# STM32L496 register map
File version: 1.0
CPU: CM4 r0p1, little endian, MPU, FPU, 4 interrupt priority bits
Registers are 32-bit, read-write, reset 0x0 unless marked. A register's access mark holds for its fields unless they carry their own. Offsets are from the block's base; [hi:lo] are bit positions; {n}, {i} and the like mark numbered series; 'fields as' and 'values as' point back to an identical list.

## USART1 — Universal synchronous asynchronous receiver transmitter
Base 0x40013800
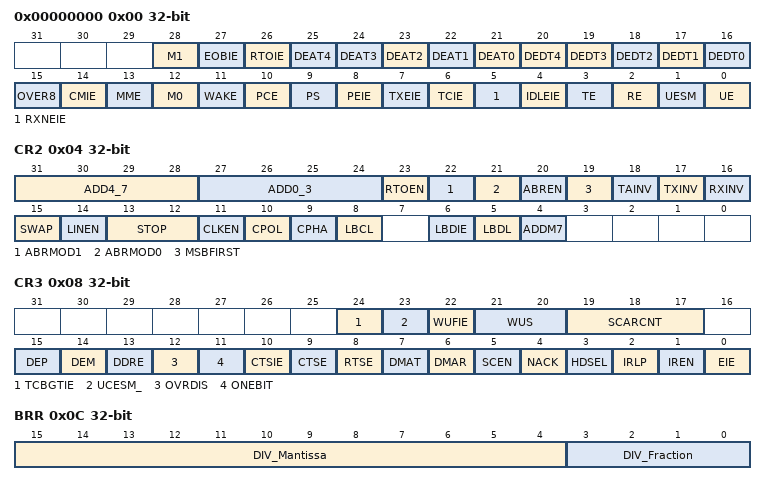
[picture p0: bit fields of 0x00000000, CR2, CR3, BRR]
0x00 0x00000000 — Control register 1
  [28] M1 — Word length
  [27] EOBIE — End of Block interrupt enable
  [26] RTOIE — Receiver timeout interrupt enable
  [25] DEAT4 — Driver Enable assertion time
  [n+21] DEAT{n} (n=0..3)
  [20] DEDT4 — Driver Enable de-assertion time
  [n+16] DEDT{n} (n=0..3)
  [15] OVER8 — Oversampling mode
  [14] CMIE — Character match interrupt enable
  [13] MME — Mute mode enable
  [12] M0 — Word length
  [11] WAKE — Receiver wakeup method
  [10] PCE — Parity control enable
  [9] PS — Parity selection
  [8] PEIE — PE interrupt enable
  [7] TXEIE — interrupt enable
  [6] TCIE — Transmission complete interrupt enable
  [5] RXNEIE — RXNE interrupt enable
  [4] IDLEIE — IDLE interrupt enable
  [3] TE — Transmitter enable
  [2] RE — Receiver enable
  [1] UESM — USART enable in Stop mode
  [0] UE — USART enable
0x04 CR2 — Control register 2
  [31:28] ADD4_7 — Address of the USART node
  [27:24] ADD0_3 — Address of the USART node
  [23] RTOEN — Receiver timeout enable
  [22] ABRMOD1 — Auto baud rate mode
  [21] ABRMOD0
  [20] ABREN — Auto baud rate enable
  [19] MSBFIRST — Most significant bit first
  [18] TAINV — Binary data inversion
  [17] TXINV — TX pin active level inversion
  [16] RXINV — RX pin active level inversion
  [15] SWAP — Swap TX/RX pins
  [14] LINEN — LIN mode enable
  [13:12] STOP — STOP bits
  [11] CLKEN — Clock enable
  [10] CPOL — Clock polarity
  [9] CPHA — Clock phase
  [8] LBCL — Last bit clock pulse
  [6] LBDIE — LIN break detection interrupt enable
  [5] LBDL — LIN break detection length
  [4] ADDM7 — 7-bit Address Detection/4-bit Address Detection
0x08 CR3 — Control register 3
  [24] TCBGTIE — Transmission complete before guard time interrupt enable
  [23] UCESM_ — USART Clock Enable in Stop mode.
  [22] WUFIE — Wakeup from Stop mode interrupt enable
  [21:20] WUS — Wakeup from Stop mode interrupt flag selection
  [19:17] SCARCNT — Smartcard auto-retry count
  [15] DEP — Driver enable polarity selection
  [14] DEM — Driver enable mode
  [13] DDRE — DMA Disable on Reception Error
  [12] OVRDIS — Overrun Disable
  [11] ONEBIT — One sample bit method enable
  [10] CTSIE — CTS interrupt enable
  [9] CTSE — CTS enable
  [8] RTSE — RTS enable
  [7] DMAT — DMA enable transmitter
  [6] DMAR — DMA enable receiver
  [5] SCEN — Smartcard mode enable
  [4] NACK — Smartcard NACK enable
  [3] HDSEL — Half-duplex selection
  [2] IRLP — Ir low-power
  [1] IREN — Ir mode enable
  [0] EIE — Error interrupt enable
0x0C BRR — Baud rate register
  [15:4] DIV_Mantissa, [3:0] DIV_Fraction
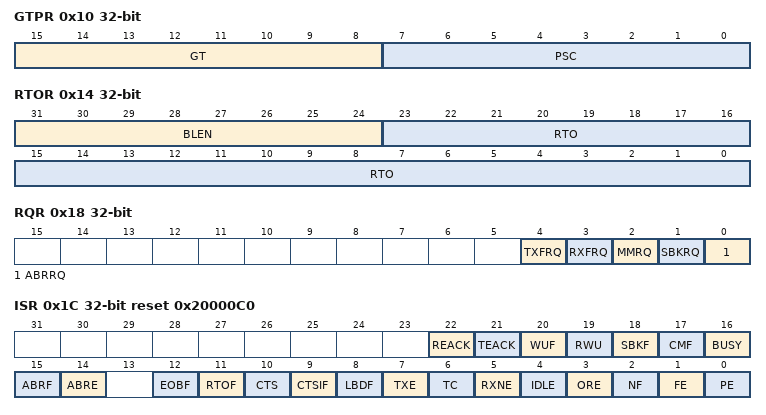
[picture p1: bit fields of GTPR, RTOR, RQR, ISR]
0x10 GTPR — Guard time and prescaler register
  [15:8] GT — Guard time value
  [7:0] PSC — Prescaler value
0x14 RTOR — Receiver timeout register
  [31:24] BLEN — Block Length
  [23:0] RTO — Receiver timeout value
0x18 RQR wo — Request register
  [4] TXFRQ — Transmit data flush request
  [3] RXFRQ — Receive data flush request
  [2] MMRQ — Mute mode request
  [1] SBKRQ — Send break request
  [0] ABRRQ — Auto baud rate request
0x1C ISR ro reset 0x20000C0 — Interrupt & status register
  [22] REACK, [21] TEACK, [20] WUF, [19] RWU, [18] SBKF, [17] CMF, [16] BUSY, [15] ABRF, [14] ABRE, [12] EOBF, [11] RTOF, [10] CTS, [9] CTSIF, [8] LBDF, [7] TXE, [6] TC, [5] RXNE, [4] IDLE, [3] ORE, [2] NF, [1] FE, [0] PE
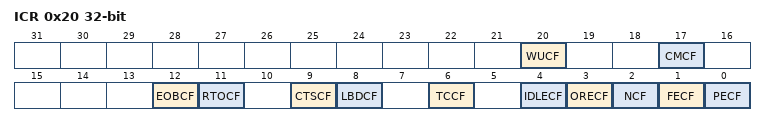
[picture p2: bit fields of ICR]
0x20 ICR wo — Interrupt flag clear register
  [20] WUCF — Wakeup from Stop mode clear flag
  [17] CMCF — Character match clear flag
  [12] EOBCF — End of block clear flag
  [11] RTOCF — Receiver timeout clear flag
  [9] CTSCF — CTS clear flag
  [8] LBDCF — LIN break detection clear flag
  [6] TCCF — Transmission complete clear flag
  [4] IDLECF — Idle line detected clear flag
  [3] ORECF — Overrun error clear flag
  [2] NCF — Noise detected clear flag
  [1] FECF — Framing error clear flag
  [0] PECF — Parity error clear flag
0x24 RDR ro — Receive data register
  [8:0] RDR — Receive data value
0x28 TDR — Transmit data register
  [8:0] TDR — Transmit data value

## USART2 — Universal synchronous asynchronous receiver transmitter
Base 0x40004400
Registers as USART1, without 0x00000000; these are added or differ:
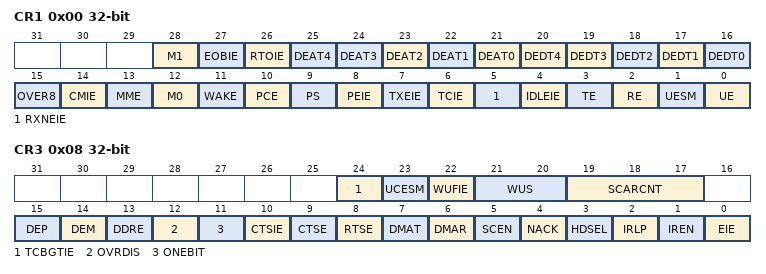
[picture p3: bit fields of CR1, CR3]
0x00 CR1 — Control register 1
  fields as USART1.0x00000000
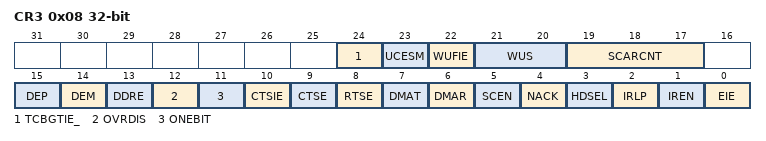
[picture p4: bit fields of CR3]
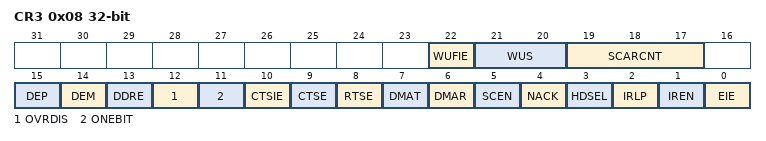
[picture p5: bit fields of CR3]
0x08 CR3 — Control register 3
  [24] TCBGTIE — Transmission complete before guard time interrupt enable
  [23] UCESM — USART Clock Enable in Stop mode.
  [22] WUFIE — Wakeup from Stop mode interrupt enable
  [21:20] WUS — Wakeup from Stop mode interrupt flag selection
  [19:17] SCARCNT — Smartcard auto-retry count
  [15] DEP — Driver enable polarity selection
  [14] DEM — Driver enable mode
  [13] DDRE — DMA Disable on Reception Error
  [12] OVRDIS — Overrun Disable
  [11] ONEBIT — One sample bit method enable
  [10] CTSIE — CTS interrupt enable
  [9] CTSE — CTS enable
  [8] RTSE — RTS enable
  [7] DMAT — DMA enable transmitter
  [6] DMAR — DMA enable receiver
  [5] SCEN — Smartcard mode enable
  [4] NACK — Smartcard NACK enable
  [3] HDSEL — Half-duplex selection
  [2] IRLP — Ir low-power
  [1] IREN — Ir mode enable
  [0] EIE — Error interrupt enable

## USART3 — Universal synchronous asynchronous receiver transmitter
Base 0x40004800
Registers as USART2; these are added or differ:
0x08 CR3 — Control register 3
  [24] TCBGTIE_ — Transmission complete before guard time interrupt enable
  [23] UCESM — USART Clock Enable in Stop mode.
  [22] WUFIE — Wakeup from Stop mode interrupt enable
  [21:20] WUS — Wakeup from Stop mode interrupt flag selection
  [19:17] SCARCNT — Smartcard auto-retry count
  [15] DEP — Driver enable polarity selection
  [14] DEM — Driver enable mode
  [13] DDRE — DMA Disable on Reception Error
  [12] OVRDIS — Overrun Disable
  [11] ONEBIT — One sample bit method enable
  [10] CTSIE — CTS interrupt enable
  [9] CTSE — CTS enable
  [8] RTSE — RTS enable
  [7] DMAT — DMA enable transmitter
  [6] DMAR — DMA enable receiver
  [5] SCEN — Smartcard mode enable
  [4] NACK — Smartcard NACK enable
  [3] HDSEL — Half-duplex selection
  [2] IRLP — Ir low-power
  [1] IREN — Ir mode enable
  [0] EIE — Error interrupt enable

## UART4 — Universal synchronous asynchronous receiver transmitter
Base 0x40004C00
Same registers: UART5 0x40005000
Registers as USART2; these are added or differ:
0x08 CR3 — Control register 3
  [22] WUFIE — Wakeup from Stop mode interrupt enable
  [21:20] WUS — Wakeup from Stop mode interrupt flag selection
  [19:17] SCARCNT — Smartcard auto-retry count
  [15] DEP — Driver enable polarity selection
  [14] DEM — Driver enable mode
  [13] DDRE — DMA Disable on Reception Error
  [12] OVRDIS — Overrun Disable
  [11] ONEBIT — One sample bit method enable
  [10] CTSIE — CTS interrupt enable
  [9] CTSE — CTS enable
  [8] RTSE — RTS enable
  [7] DMAT — DMA enable transmitter
  [6] DMAR — DMA enable receiver
  [5] SCEN — Smartcard mode enable
  [4] NACK — Smartcard NACK enable
  [3] HDSEL — Half-duplex selection
  [2] IRLP — Ir low-power
  [1] IREN — Ir mode enable
  [0] EIE — Error interrupt enable
